# ATA5790 device description
Architecture: AVR8; Family: megaAVR
Registers are 8-bit, access not given, no defined reset value unless marked. A register's access mark holds for its fields unless they carry their own. Offsets are from the block's base; [hi:lo] are bit positions; {n}, {i} and the like mark numbered series.

## AFE
Instances: AFE 0x00
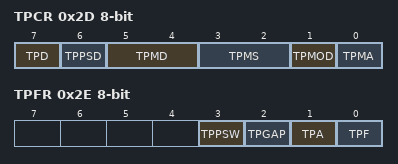
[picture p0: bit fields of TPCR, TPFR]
0x2D TPCR — Transponder Control Register
  [7] TPD — Transponder Disable Bit
  [6] TPPSD — Transponder Power Switch Disable Bit
  [5:4] TPMD — Transponder Modulation Damping level select Bit1
  [3:2] TPMS — Transponder Modulation Select Bits
  [1] TPMOD — Transponder Modulator Bit
  [0] TPMA — Transponder Mode Acknowledgment Bit
0x2E TPFR — Transponder Status & Flag Register
  [3] TPPSW — Transponder Power Switch Bit
  [2] TPGAP — Transponder Gap Signal Bit
  [1] TPA — Transponder Active Bit
  [0] TPF — Transponder Flag
0x9C TPIMR — Transponder Interrupt Mask Register
  [0] TPIM — Transponder Interrupt Mask Bit

## DDDLFRX
Instances: DDDLFRX 0x00
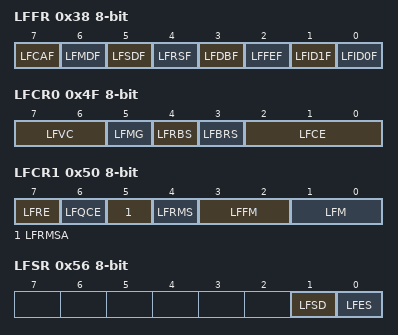
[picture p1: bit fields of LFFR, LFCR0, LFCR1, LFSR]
0x38 LFFR — LF Flag Register
  [7] LFCAF — LF Clock Adjustment Flag
  [6] LFMDF — LF Manchester Decoder Error Flag
  [5] LFSDF — LF Signal Detect Flag
  [4] LFRSF — LF RSSI Data Flag
  [3] LFDBF — LF Data Buffer Full Flag
  [2] LFFEF — LF Frame End Flag
  [1] LFID1F — LF Identifier 1 Flag
  [0] LFID0F — LF Identifier 0 Flag
0x4F LFCR0 — Low Frequency Receiver Control Register 0
  [7:6] LFVC — LF Receiver Velocity Control Bits
  [5] LFMG — LF receiver Max Gain Bit
  [4] LFRBS — LF Receiver Buffer Data Frame Select Bit
  [3] LFBRS — LF receiver Baud Rate Select Bit
  [2:0] LFCE (bit 1 of the value upward) — LF receiver Channel Enable Bits
0x50 LFCR1 — LF receiver Control Register 1
  [7] LFRE — LF Receiver Enable Bit
  [6] LFQCE — LF Receiver Quality Check Bit
  [5] LFRMSA — LF receiver Rssi Measurement Start Additional Bit
  [4] LFRMS — LF receiver RSSI Measurement Start Bit
  [3:2] LFFM — LF Function Mode Bits
  [1:0] LFM — LF Mode Bits
0x52 LFRDB — LF Receiver Data Buffer
0x56 LFSR — LF Status Register
  [1] LFSD — LF Signal Data Bit
  [0] LFES — LF Envelope Signal Bit
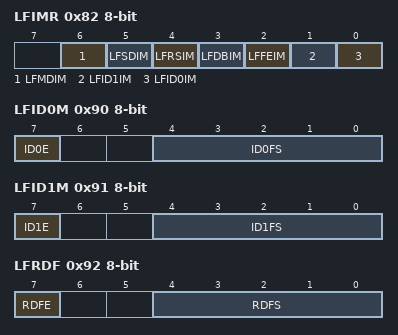
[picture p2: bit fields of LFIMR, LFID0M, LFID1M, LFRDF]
0x82 LFIMR — LF Interrupt Mask Register
  [6] LFMDIM — LF Manchester Decoder Error Interrupt Mask Bit
  [5] LFSDIM — LF Signal Detected Interrupt Mask Bit
  [4] LFRSIM — LF RSSI Data Interrupt Mask Bit
  [3] LFDBIM — LF Receiver Data Buffer Interrupt Mask Bit
  [2] LFFEIM — LF Receiver Frame End Interrupt Mask Bit
  [1] LFID1IM — LF Identifier 1 Interrupt Mask Bit
  [0] LFID0IM — LF Identifier 0 Interrupt Mask Bit
0x83 LFCAD — LF Clock Adjustment Data Register
{0x84+i} LFID{i:02} (i=0..3) — LF ID 0 Data Register Byte {i}
{0x7E+i} LFID{i} (i=10..13) — LF ID 1 Data Register Byte {i-10}
{0x8C+i} LFRD{i} (i=0..3) — LF Receive Data Register Byte {i}
0x90 LFID0M — LF Identifier 0 Mask Register
  [7] ID0E — Identifier 0 Enable Bit
  [4:0] ID0FS — Identifier 0 Frame Select Bits
0x91 LFID1M — LF Identifier 1 Mask Register
  [7] ID1E — Identifier 1 Enable Bit
  [4:0] ID1FS — Identifier 1 Frame Select Bits
0x92 LFRDF — LF Receive Data Frame Register
  [7] RDFE — Receive Data Frame Enable Bit
  [4:0] RDFS — Receive Data Frame Select Bits
{0x92+i} LFRSD{i} (i=1..3) — LF RSSI Data Register {i}
{0x95+i} LFCC{i} bits used 3:0 (i=1..3) — Low Frequency Channel Capacity select register {i}

## IRLED
Instances: IRLED 0x00
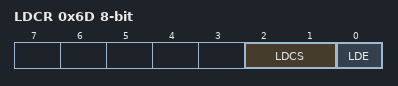
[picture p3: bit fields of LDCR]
0x6D LDCR — LED Driver Control Register
  [2:1] LDCS — LED Driver Current Select Bits
  [0] LDE — LED Driver Enable Bit

## AES
Instances: AES 0x00
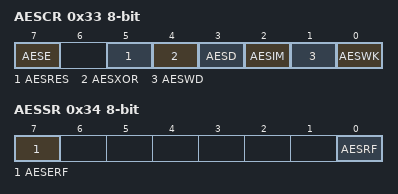
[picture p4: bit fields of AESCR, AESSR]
0x33 AESCR — AES Control Register
  [7] AESE — AES Enable Bit
  [5] AESRES — AES Reset Bit
  [4] AESXOR — AES State XOR load bit
  [3] AESD — AES Direction Bit
  [2] AESIM — AES Interrupt Mask Bit
  [1] AESWD — AES Write Data Bit
  [0] AESWK — AES Write Key Bit
0x34 AESSR — AES Status Register
  [7] AESERF — AES Error Flag Bit
  [0] AESRF — AES Ready Flag Bit
0x49 AESDR — AES Data Register
0x4A AESKR — AES Key Register
  [7:0] AESKR — AES Key Register Bits

## MOD
Instances: MOD 0x00
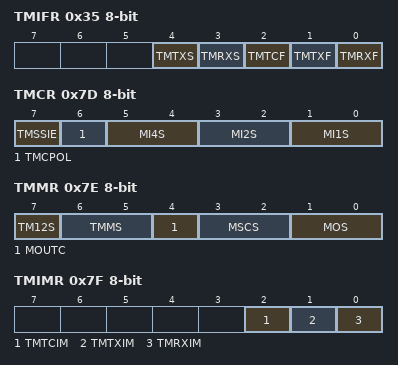
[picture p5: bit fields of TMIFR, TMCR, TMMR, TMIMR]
0x35 TMIFR — Timer Modulator Interrupt Flag Register
  [4] TMTXS — Timer Modulator SSI Transmit Status Bit
  [3] TMRXS — Timer Modulator SSI Receive Status Bit
  [2] TMTCF — Timer Modulator SSI Transmit Complete Flag Bit
  [1] TMTXF — Timer Modulator SSI Transmit Flag Bit
  [0] TMRXF — Timer Modulator SSI Receive Flag Bit
0x48 TMDR — Timer Modulator Data Register
0x7D TMCR — Timer Modulator Control Register
  [7] TMSSIE — Timer Modulator SSI Enable Bit
  [6] TMCPOL — Timer Modulator Clock Polarity for SSI shift clock
  [5:4] MI4S — Modulator Interface 4 Select Bits
  [3:2] MI2S — Modulator Interface 2 Select Bits
  [1:0] MI1S — Modulator Interface 1 Select Bits
0x7E TMMR — Timer Modulator Mode Register
  [7] TM12S — Timer Modulator 1/2 output Select bit
  [6:5] TMMS — Timer Modulator Mode Select Bits
  [4] MOUTC — Modulator OUT signal Complement Bit
  [3:2] MSCS — Modulator Shift Clock Select Bits
  [1:0] MOS — Modulator Output Select Bits
0x7F TMIMR — Timer Modulator Interrupt Mask Register
  [2] TMTCIM — Timer Modulator SSI Transmit Complete Interrupt Mask Bit
  [1] TMTXIM — Timer Modulator SSI Transmit Interrupt Mask Bit
  [0] TMRXIM — Timer Modulator SSI Receive Interrupt Mask Bit
0xA8 TMMDR bits used 3:0 — Timer Modulator Manchester Data Register
0xA9 TMBDR bits used 3:0 — Timer Modulator Biphase Data Register
0xAA TMTDR — Timer Modulator Transmit Data Register
0xAB TMSR — Timer Modulator Shift Register
